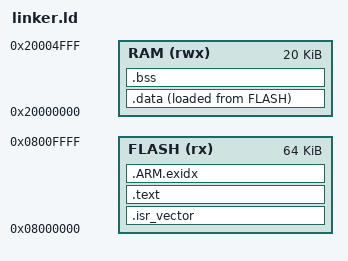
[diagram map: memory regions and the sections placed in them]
ENTRY(Reset_Handler)

MEMORY
{
  FLASH (rx)  : ORIGIN = 0x08000000, LENGTH = 64K
  RAM   (rwx) : ORIGIN = 0x20000000, LENGTH = 20K
}

_estack = ORIGIN(RAM) + LENGTH(RAM);

SECTIONS
{
  .isr_vector :
  {
    KEEP(*(.isr_vector))
  } > FLASH

  .text :
  {
    *(.text*)
    *(.rodata*)
    KEEP(*(.init))
    KEEP(*(.fini))
  } > FLASH

  .ARM.exidx :
  {
    __exidx_start = .;
    *(.ARM.exidx*)
    __exidx_end = .;
  } > FLASH

  _sidata = LOADADDR(.data);

  .data :
  {
    _sdata = .;
    *(.data*)
    _edata = .;
  } > RAM AT > FLASH

  .bss :
  {
    _sbss = .;
    *(.bss*)
    *(COMMON)
    _ebss = .;
  } > RAM

  _end = .;
  end = .;
  __end__ = .;
}
/* Reserve RAM for stack; .bss/.data must not grow into this region. */
ASSERT(_end <= _estack - 0x800, "Static RAM overlaps reserved 2 KB stack")
